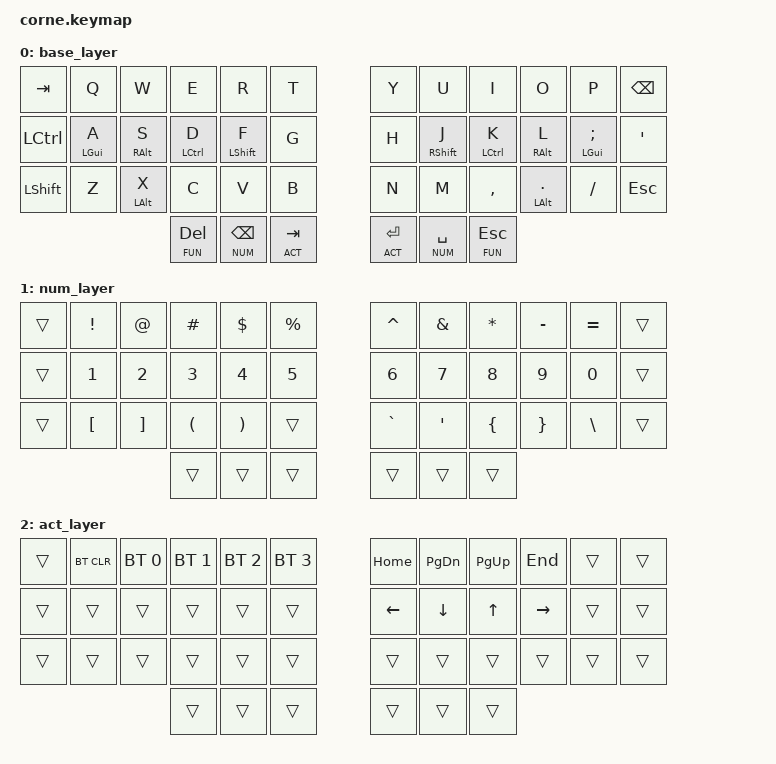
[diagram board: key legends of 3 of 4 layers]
#include <behaviors.dtsi>
#include <dt-bindings/zmk/keys.h>
#include <dt-bindings/zmk/bt.h>

#define BASE 0
#define NUM  1
#define ACT  2
#define FUN  3

/ {
    behaviors {
        hm: homerow_mods {
            compatible = "zmk,behavior-hold-tap";
            #binding-cells = <2>;
            tapping-term-ms = <280>;
            quick-tap-ms = <175>;
            require-prior-idle-ms = <150>;
            flavor = "balanced";
            bindings = <&kp>, <&kp>;
        };
        
        // Layer-tap with repeat: tap-then-hold repeats the tap key
        ltr: layer_tap_repeat {
            compatible = "zmk,behavior-hold-tap";
            #binding-cells = <2>;
            tapping-term-ms = <200>;
            quick-tap-ms = <175>;     // <-- this is the key part
            flavor = "tap-preferred";
            bindings = <&mo>, <&kp>;
        };
    };

    keymap {
        compatible = "zmk,keymap";

        base_layer {
            bindings = <
//              ╭─────────────┬─────────────┬─────────────┬─────────────┬─────────────╮   ╭─────────────┬─────────────┬─────────────┬─────────────┬─────────────╮
    &kp TAB      &kp Q         &kp W         &kp E         &kp R         &kp T             &kp Y         &kp U         &kp I         &kp O         &kp P         &kp BSPC
//              ├─────────────┼─────────────┼─────────────┼─────────────┼─────────────┤   ├─────────────┼─────────────┼─────────────┼─────────────┼─────────────┤
    &kp LCTRL    &hm LGUI A    &hm RALT S    &hm LCTRL D   &hm LSHFT F   &kp G             &kp H         &hm RSHFT J   &hm LCTRL K   &hm RALT L    &hm LGUI SEMI &kp SQT
//              ├─────────────┼─────────────┼─────────────┼─────────────┼─────────────┤   ├─────────────┼─────────────┼─────────────┼─────────────┼─────────────┤
    &kp LSHFT    &kp Z         &hm LALT X    &kp C         &kp V         &kp B             &kp N         &kp M         &kp COMMA     &hm LALT DOT  &kp FSLH      &kp ESC
//              ╰─────────────┴─────────────┴─────────────┼─────────────┼─────────────┼───┼─────────────┼─────────────┼─────────────┴─────────────┴─────────────╯
                                             &ltr FUN DEL  &ltr NUM BSPC &ltr ACT TAB      &ltr ACT RET  &ltr NUM SPACE &ltr FUN ESC
//                                          ╰─────────────┴─────────────┴─────────────┴───┴─────────────┴─────────────┴─────────────╯
            >;
        };

        // Numbers on home row, symbols on upper row
        num_layer {
            bindings = <
//              ╭─────────────┬─────────────┬─────────────┬─────────────┬─────────────╮   ╭─────────────┬─────────────┬─────────────┬─────────────┬─────────────╮
    &trans       &kp EXCL      &kp AT        &kp HASH      &kp DLLR      &kp PRCNT         &kp CARET     &kp AMPS      &kp ASTRK     &kp MINUS     &kp EQUAL     &trans
//              ├─────────────┼─────────────┼─────────────┼─────────────┼─────────────┤   ├─────────────┼─────────────┼─────────────┼─────────────┼─────────────┤
    &trans       &kp N1        &kp N2        &kp N3        &kp N4        &kp N5            &kp N6        &kp N7        &kp N8        &kp N9        &kp N0        &trans
//              ├─────────────┼─────────────┼─────────────┼─────────────┼─────────────┤   ├─────────────┼─────────────┼─────────────┼─────────────┼─────────────┤
    &trans       &kp LBKT      &kp RBKT      &kp LPAR      &kp RPAR      &trans            &kp GRAVE     &kp SQT       &kp LBRC      &kp RBRC      &kp BSLH      &trans
//              ╰─────────────┴─────────────┴─────────────┼─────────────┼─────────────┼───┼─────────────┼─────────────┼─────────────┴─────────────┴─────────────╯
                                             &trans        &trans        &trans            &trans        &trans        &trans
//                                          ╰─────────────┴─────────────┴─────────────┴───┴─────────────┴─────────────┴─────────────╯
            >;
        };

        // Symbols — brackets/pairs on left · operators/punctuation on right
        act_layer {
            bindings = <
//              ╭─────────────┬─────────────┬─────────────┬─────────────┬─────────────╮   ╭─────────────┬─────────────┬─────────────┬─────────────┬─────────────╮
    &trans       &bt BT_CLR    &bt BT_SEL 0  &bt BT_SEL 1  &bt BT_SEL 2  &bt BT_SEL 3      &kp HOME      &kp PG_DN     &kp PG_UP     &kp END       &trans        &trans
//              ├─────────────┼─────────────┼─────────────┼─────────────┼─────────────┤   ├─────────────┼─────────────┼─────────────┼─────────────┼─────────────┤
    &trans       &trans        &trans        &trans        &trans        &trans            &kp LEFT      &kp DOWN      &kp UP        &kp RIGHT     &trans        &trans
//              ├─────────────┼─────────────┼─────────────┼─────────────┼─────────────┤   ├─────────────┼─────────────┼─────────────┼─────────────┼─────────────┤
    &trans       &trans        &trans        &trans        &trans        &trans            &trans        &trans        &trans        &trans        &trans        &trans
//              ╰─────────────┴─────────────┴─────────────┼─────────────┼─────────────┼───┼─────────────┼─────────────┼─────────────┴─────────────┴─────────────╯
                                             &trans        &trans        &trans            &trans        &trans        &trans
//                                          ╰─────────────┴─────────────┴─────────────┴───┴─────────────┴─────────────┴─────────────╯
            >;
        };

        // F1–F10 on top row · F11–F12 on right home row
        fun_layer {
            bindings = <
//              ╭─────────────┬─────────────┬─────────────┬─────────────┬─────────────╮   ╭─────────────┬─────────────┬─────────────┬─────────────┬─────────────╮
    &trans       &trans        &trans        &kp C_VOL_DN  &kp C_VOL_UP   &kp C_MUTE         &trans        &trans        &trans        &trans        &trans       &trans
//              ├─────────────┼─────────────┼─────────────┼─────────────┼─────────────┤   ├─────────────┼─────────────┼─────────────┼─────────────┼─────────────┤
    &trans       &kp F1        &kp F2        &kp F3        &kp F4         &kp F5             &kp F6        &kp F7        &kp F8        &kp F9        &kp F10      &trans
//              ├─────────────┼─────────────┼─────────────┼─────────────┼─────────────┤   ├─────────────┼─────────────┼─────────────┼─────────────┼─────────────┤
    &trans       &trans        &trans        &kp C_PP      &kp C_PREV     &kp C_NEXT         &trans        &trans        &kp F11       &kp F12      &trans
//              ╰─────────────┴─────────────┴─────────────┼─────────────┼─────────────┼───┼─────────────┼─────────────┼─────────────┴─────────────┴─────────────╯
                                             &trans        &trans         &trans             &trans        &trans        &trans
//                                          ╰─────────────┴─────────────┴─────────────┴───┴─────────────┴─────────────┴─────────────╯
            >;
        };
    };
};
